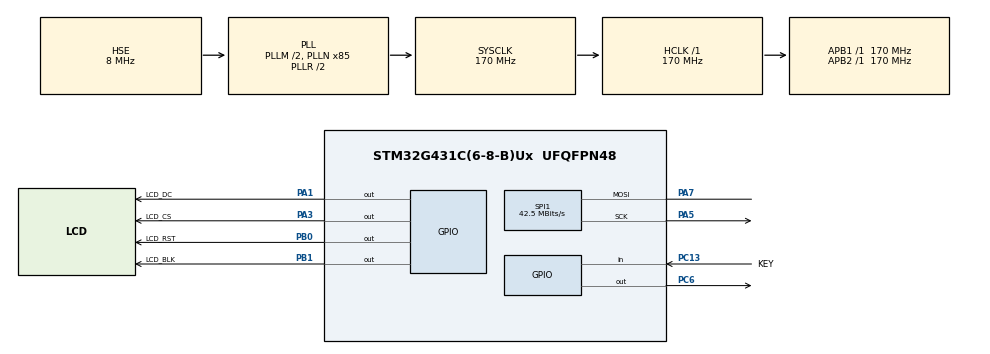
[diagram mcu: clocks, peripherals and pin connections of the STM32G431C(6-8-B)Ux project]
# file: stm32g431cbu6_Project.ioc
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Dma.Request0=SPI1_TX
Dma.SPI1_TX.0.Direction=DMA_MEMORY_TO_PERIPH
Dma.SPI1_TX.0.EventEnable=DISABLE
Dma.SPI1_TX.0.Instance=DMA1_Channel2
Dma.SPI1_TX.0.MemDataAlignment=DMA_MDATAALIGN_HALFWORD
Dma.SPI1_TX.0.MemInc=DMA_MINC_ENABLE
Dma.SPI1_TX.0.Mode=DMA_NORMAL
Dma.SPI1_TX.0.PeriphDataAlignment=DMA_PDATAALIGN_HALFWORD
Dma.SPI1_TX.0.PeriphInc=DMA_PINC_DISABLE
Dma.SPI1_TX.0.Polarity=HAL_DMAMUX_REQ_GEN_RISING
Dma.SPI1_TX.0.Priority=DMA_PRIORITY_LOW
Dma.SPI1_TX.0.RequestNumber=1
Dma.SPI1_TX.0.SignalID=NONE
Dma.SPI1_TX.0.SyncEnable=DISABLE
Dma.SPI1_TX.0.SyncPolarity=HAL_DMAMUX_SYNC_NO_EVENT
Dma.SPI1_TX.0.SyncRequestNumber=1
Dma.SPI1_TX.0.SyncSignalID=NONE
Mcu.Family=STM32G4
Mcu.Name=STM32G431C(6-8-B)Ux
Mcu.Package=UFQFPN48
NVIC.DMA1_Channel2_IRQn=true\:0\:0\:false\:false\:true\:true\:true\:true
NVIC.PriorityGroup=NVIC_PRIORITYGROUP_4
PA1.GPIO_Label=LCD_DC
PA1.GPIO_Speed=GPIO_SPEED_FREQ_HIGH
PA1.PinState=GPIO_PIN_SET
PA1.Signal=GPIO_Output
PA13.Mode=Serial_Wire
PA13.Signal=SYS_JTMS-SWDIO
PA14.Mode=Serial_Wire
PA14.Signal=SYS_JTCK-SWCLK
PA3.GPIO_Label=LCD_CS
PA3.GPIO_Speed=GPIO_SPEED_FREQ_HIGH
PA3.PinState=GPIO_PIN_SET
PA3.Signal=GPIO_Output
PA5.GPIO_Speed=GPIO_SPEED_FREQ_VERY_HIGH
PA5.Mode=Simplex_Bidirectional_Master
PA5.Signal=SPI1_SCK
PA7.GPIO_Speed=GPIO_SPEED_FREQ_VERY_HIGH
PA7.Mode=Simplex_Bidirectional_Master
PA7.Signal=SPI1_MOSI
PB0.GPIO_Label=LCD_RST
PB0.GPIO_Speed=GPIO_SPEED_FREQ_HIGH
PB0.PinState=GPIO_PIN_SET
PB0.Signal=GPIO_Output
PB1.GPIO_Label=LCD_BLK
PB1.GPIO_Speed=GPIO_SPEED_FREQ_HIGH
PB1.PinState=GPIO_PIN_RESET
PB1.Signal=GPIO_Output
PC13.GPIO_Label=KEY
PC13.GPIO_PuPd=GPIO_PULLDOWN
PC13.Signal=GPIO_Input
PC14-OSC32_IN.Mode=LSE-External-Oscillator
PC14-OSC32_IN.Signal=RCC_OSC32_IN
PC15-OSC32_OUT.Mode=LSE-External-Oscillator
PC15-OSC32_OUT.Signal=RCC_OSC32_OUT
PC6.GPIO_PuPd=GPIO_PULLUP
PC6.GPIO_Speed=GPIO_SPEED_FREQ_HIGH
PC6.PinState=GPIO_PIN_SET
PC6.Signal=GPIO_Output
PF0-OSC_IN.Mode=HSE-External-Oscillator
PF0-OSC_IN.Signal=RCC_OSC_IN
PF1-OSC_OUT.Mode=HSE-External-Oscillator
PF1-OSC_OUT.Signal=RCC_OSC_OUT
ProjectManager.HeapSize=0x200
ProjectManager.StackSize=0x400
ProjectManager.TargetToolchain=STM32CubeIDE
RCC.ADC12Freq_Value=170000000
RCC.AHBFreq_Value=170000000
RCC.APB1Freq_Value=170000000
RCC.APB1TimFreq_Value=170000000
RCC.APB2Freq_Value=170000000
RCC.APB2TimFreq_Value=170000000
RCC.CortexFreq_Value=170000000
RCC.EXTERNAL_CLOCK_VALUE=12288000
RCC.HCLKFreq_Value=170000000
RCC.HSE_VALUE=8000000
RCC.HSI48_VALUE=48000000
RCC.HSI_VALUE=16000000
RCC.PLLM=RCC_PLLM_DIV2
RCC.PLLN=85
RCC.PLLSourceVirtual=RCC_PLLSOURCE_HSE
RCC.SYSCLKFreq_VALUE=170000000
RCC.SYSCLKSource=RCC_SYSCLKSOURCE_PLLCLK
RCC.USBFreq_Value=170000000
RCC.VCOOutputFreq_Value=340000000
SPI1.BaudRatePrescaler=SPI_BAUDRATEPRESCALER_4
SPI1.CLKPhase=SPI_PHASE_1EDGE
SPI1.CLKPolarity=SPI_POLARITY_LOW
SPI1.CRCCalculation=SPI_CRCCALCULATION_DISABLE
SPI1.CalculateBaudRate=42.5 MBits/s
SPI1.DataSize=SPI_DATASIZE_8BIT
SPI1.Direction=SPI_DIRECTION_1LINE
SPI1.FirstBit=SPI_FIRSTBIT_MSB
SPI1.Mode=SPI_MODE_MASTER
SPI1.NSS=SPI_NSS_SOFT
SPI1.NSSPMode=SPI_NSS_PULSE_DISABLE
SPI1.VirtualNSS=VM_NSSSOFT
SPI1.VirtualType=VM_MASTER
VP_SYS_VS_DBSignals.Mode=DisableDeadBatterySignals
board=custom

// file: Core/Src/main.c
/* USER CODE BEGIN Header */
/**
  ******************************************************************************
  * @file           : main.c
  * @brief          : Main program body
  ******************************************************************************
  * @attention
  *
  * Copyright (c) 2026 STMicroelectronics.
  * All rights reserved.
  *
  * This software is licensed under terms that can be found in the LICENSE file
  * in the root directory of this software component.
  * If no LICENSE file comes with this software, it is provided AS-IS.
  *
  ******************************************************************************
  */
/* USER CODE END Header */
#include "main.h"
#include "dma.h"
#include "spi.h"
#include "gpio.h"

/* USER CODE BEGIN Includes */
/* Code added inside the USER CODE sections of this project is
   Apache-2.0, Copyright (C) 2026 CytStudio <cyte_studio@foxmail.com>.
   The rest of this file is STMicroelectronics BSD-3-Clause, see
   Drivers/STM32G4xx_HAL_Driver/LICENSE.txt. */
#include "app.h"
/* USER CODE END Includes */

void SystemClock_Config(void);

int main(void)
{

  /* MCU Configuration--------------------------------------------------------*/

  /* Reset of all peripherals, Initializes the Flash interface and the Systick. */
  HAL_Init();

  /* Configure the system clock */
  SystemClock_Config();

  /* Initialize all configured peripherals */
  MX_GPIO_Init();
  MX_DMA_Init();
  MX_SPI1_Init();
  /* USER CODE BEGIN 2 */
  /* GPIO、DMA1_Channel2 和 SPI1 上面已经由 .ioc 生成的初始化配好了，
     BSP 只拿 hspi1 用。 */
  if (app_init() != 0)
  {
    Error_Handler();
  }
  /* USER CODE END 2 */

  /* Infinite loop */
  while (1)
  {

    /* USER CODE BEGIN 3 */
    app_run();
  }
  /* USER CODE END 3 */
}

void SystemClock_Config(void)
{
  RCC_OscInitTypeDef RCC_OscInitStruct = {0};
  RCC_ClkInitTypeDef RCC_ClkInitStruct = {0};

  /** Configure the main internal regulator output voltage
  */
  HAL_PWREx_ControlVoltageScaling(PWR_REGULATOR_VOLTAGE_SCALE1_BOOST);

  /** Initializes the RCC Oscillators according to the specified parameters
  * in the RCC_OscInitTypeDef structure.
  */
  RCC_OscInitStruct.OscillatorType = RCC_OSCILLATORTYPE_HSE;
  RCC_OscInitStruct.HSEState = RCC_HSE_ON;
  RCC_OscInitStruct.PLL.PLLState = RCC_PLL_ON;
  RCC_OscInitStruct.PLL.PLLSource = RCC_PLLSOURCE_HSE;
  RCC_OscInitStruct.PLL.PLLM = RCC_PLLM_DIV2;
  RCC_OscInitStruct.PLL.PLLN = 85;
  RCC_OscInitStruct.PLL.PLLP = RCC_PLLP_DIV2;
  RCC_OscInitStruct.PLL.PLLQ = RCC_PLLQ_DIV2;
  RCC_OscInitStruct.PLL.PLLR = RCC_PLLR_DIV2;
  if (HAL_RCC_OscConfig(&RCC_OscInitStruct) != HAL_OK)
  {
    Error_Handler();
  }

  /** Initializes the CPU, AHB and APB buses clocks
  */
  RCC_ClkInitStruct.ClockType = RCC_CLOCKTYPE_HCLK|RCC_CLOCKTYPE_SYSCLK
                              |RCC_CLOCKTYPE_PCLK1|RCC_CLOCKTYPE_PCLK2;
  RCC_ClkInitStruct.SYSCLKSource = RCC_SYSCLKSOURCE_PLLCLK;
  RCC_ClkInitStruct.AHBCLKDivider = RCC_SYSCLK_DIV1;
  RCC_ClkInitStruct.APB1CLKDivider = RCC_HCLK_DIV1;
  RCC_ClkInitStruct.APB2CLKDivider = RCC_HCLK_DIV1;

  if (HAL_RCC_ClockConfig(&RCC_ClkInitStruct, FLASH_LATENCY_4) != HAL_OK)
  {
    Error_Handler();
  }
}

void Error_Handler(void)
{
  __disable_irq();
  while (1)
  {
  }
}
